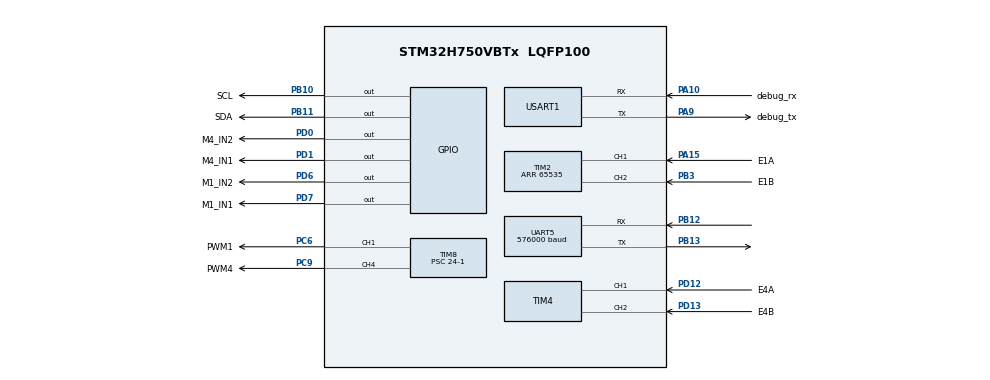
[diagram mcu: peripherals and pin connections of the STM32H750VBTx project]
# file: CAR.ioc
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CORTEX_M7.default_mode_Activation=1
Mcu.Family=STM32H7
Mcu.Name=STM32H750VBTx
Mcu.Package=LQFP100
NVIC.PriorityGroup=NVIC_PRIORITYGROUP_4
NVIC.TIM1_UP_IRQn=true\:15\:0\:false\:false\:true\:false\:true\:true
NVIC.TIM3_IRQn=true\:3\:0\:true\:false\:true\:true\:true\:true
NVIC.TimeBase=TIM1_UP_IRQn
NVIC.TimeBaseIP=TIM1
NVIC.UART5_IRQn=true\:2\:0\:true\:false\:true\:true\:true\:true
PA10.GPIO_Label=debug_rx
PA10.Mode=Asynchronous
PA10.Signal=USART1_RX
PA13\ (JTMS/SWDIO).Signal=DEBUG_JTMS-SWDIO
PA15\ (JTDI).GPIO_Label=E1A
PA15\ (JTDI).Signal=S_TIM2_CH1_ETR
PA9.GPIO_Label=debug_tx
PA9.Mode=Asynchronous
PA9.Signal=USART1_TX
PB10.GPIO_Label=SCL
PB10.GPIO_ModeDefaultOutputPP=GPIO_MODE_OUTPUT_OD
PB10.GPIO_PuPd=GPIO_NOPULL
PB10.GPIO_Speed=GPIO_SPEED_FREQ_HIGH
PB10.PinState=GPIO_PIN_SET
PB10.Signal=GPIO_Output
PB11.GPIO_Label=SDA
PB11.GPIO_ModeDefaultOutputPP=GPIO_MODE_OUTPUT_OD
PB11.GPIO_PuPd=GPIO_NOPULL
PB11.GPIO_Speed=GPIO_SPEED_FREQ_HIGH
PB11.PinState=GPIO_PIN_SET
PB11.Signal=GPIO_Output
PB12.Mode=Asynchronous
PB12.Signal=UART5_RX
PB13.Mode=Asynchronous
PB13.Signal=UART5_TX
PB3\ (JTDO/TRACESWO).GPIO_Label=E1B
PB3\ (JTDO/TRACESWO).Signal=S_TIM2_CH2
PC6.GPIO_Label=PWM1
PC6.Signal=S_TIM8_CH1
PC9.GPIO_Label=PWM4
PC9.Signal=S_TIM8_CH4
PD0.GPIO_Label=M4_IN2
PD0.Signal=GPIO_Output
PD1.GPIO_Label=M4_IN1
PD1.Signal=GPIO_Output
PD12.GPIO_Label=E4A
PD12.Signal=S_TIM4_CH1
PD13.GPIO_Label=E4B
PD13.Signal=S_TIM4_CH2
PD6.GPIO_Label=M1_IN2
PD6.Signal=GPIO_Output
PD7.GPIO_Label=M1_IN1
PD7.Signal=GPIO_Output
PH0-OSC_IN\ (PH0).Mode=HSE-External-Oscillator
PH0-OSC_IN\ (PH0).Signal=RCC_OSC_IN
PH1-OSC_OUT\ (PH1).Mode=HSE-External-Oscillator
PH1-OSC_OUT\ (PH1).Signal=RCC_OSC_OUT
ProjectManager.HeapSize=0x200
ProjectManager.StackSize=0x400
ProjectManager.TargetToolchain=MDK-ARM V5.32
RCC.ADCFreq_Value=24187500
RCC.APB1Freq_Value=120000000
RCC.APB2Freq_Value=120000000
RCC.APB3Freq_Value=120000000
RCC.APB4Freq_Value=120000000
RCC.CortexFreq_Value=480000000
RCC.D1PPRE=RCC_APB3_DIV2
RCC.D2PPRE1=RCC_APB1_DIV2
RCC.D2PPRE2=RCC_APB2_DIV2
RCC.D3PPRE=RCC_APB4_DIV2
RCC.DIVM1=1
RCC.DIVN1=80
RCC.HCLKFreq_Value=240000000
RCC.HPRE=RCC_HCLK_DIV2
RCC.HSE_VALUE=12000000
RCC.PLL2FRACN=0
RCC.PLL3FRACN=0
RCC.PLLFRACN=0
RCC.PLLSourceVirtual=RCC_PLLSOURCE_HSE
RCC.SYSCLKFreq_VALUE=480000000
RCC.SYSCLKSource=RCC_SYSCLKSOURCE_PLLCLK
RCC.USBFreq_Value=480000000
SH.S_TIM2_CH1_ETR.0=TIM2_CH1,Encoder_Interface
SH.S_TIM2_CH2.0=TIM2_CH2,Encoder_Interface
SH.S_TIM4_CH1.0=TIM4_CH1,Encoder_Interface
SH.S_TIM4_CH2.0=TIM4_CH2,Encoder_Interface
SH.S_TIM8_CH1.0=TIM8_CH1,PWM Generation1 CH1
SH.S_TIM8_CH4.0=TIM8_CH4,PWM Generation4 CH4
TIM2.EncoderMode=TIM_ENCODERMODE_TI12
TIM2.IC1Filter=10
TIM2.IC2Filter=10
TIM2.Period=65535
TIM3.Period=20-1
TIM3.Prescaler=24-1
TIM4.EncoderMode=TIM_ENCODERMODE_TI12
TIM4.IC1Filter=10
TIM4.IC2Filter=10
TIM8.Channel-PWM\ Generation1\ CH1=TIM_CHANNEL_1
TIM8.Channel-PWM\ Generation4\ CH4=TIM_CHANNEL_4
TIM8.Period=1000-1
TIM8.Prescaler=24-1
UART5.BaudRate=576000
USART1.VirtualMode-Asynchronous=VM_ASYNC
VP_MEMORYMAP_VS_MEMORYMAP.Mode=CurAppReg
VP_SYS_VS_tim1.Mode=TIM1
VP_TIM3_VS_ClockSourceINT.Mode=Internal
board=custom

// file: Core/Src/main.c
/* USER CODE BEGIN Header */
/**
  ******************************************************************************
  * @file           : main.c
  * @brief          : Main program body
  ******************************************************************************
  * @attention
  *
  * Copyright (c) 2026 STMicroelectronics.
  * All rights reserved.
  *
  * This software is licensed under terms that can be found in the LICENSE file
  * in the root directory of this software component.
  * If no LICENSE file comes with this software, it is provided AS-IS.
  *
  ******************************************************************************
  */
/* USER CODE END Header */
#include "main.h"
#include "memorymap.h"
#include "tim.h"
#include "usart.h"
#include "gpio.h"

/* USER CODE BEGIN Includes */
#include "Car.h"
#include "ros_protocol.h"
/* USER CODE END Includes */

void SystemClock_Config(void);
static void MPU_Config(void);

int main(void)
{

  /* MPU Configuration--------------------------------------------------------*/
  MPU_Config();

  /* MCU Configuration--------------------------------------------------------*/

  /* Reset of all peripherals, Initializes the Flash interface and the Systick. */
  HAL_Init();

  /* Configure the system clock */
  SystemClock_Config();

  /* Initialize all configured peripherals */
  MX_GPIO_Init();
  MX_TIM2_Init();
  MX_TIM4_Init();
  MX_TIM8_Init();
  MX_USART1_UART_Init();
  MX_TIM3_Init();
  MX_UART5_Init();
  /* USER CODE BEGIN 2 */
    HAL_TIM_PWM_Start(&htim8, TIM_CHANNEL_1);
    HAL_TIM_PWM_Start(&htim8, TIM_CHANNEL_4);
    HAL_TIM_Encoder_Start(&htim4, TIM_CHANNEL_ALL);
    HAL_TIM_Encoder_Start(&htim2, TIM_CHANNEL_ALL);
    RosProtocol_Init(&huart5);
  /* USER CODE END 2 */

  /* Infinite loop */
  /* USER CODE BEGIN WHILE */
    Car_Init();
  while (1)
  {

    /* USER CODE END WHILE */

  }
}

void SystemClock_Config(void)
{
  RCC_OscInitTypeDef RCC_OscInitStruct = {0};
  RCC_ClkInitTypeDef RCC_ClkInitStruct = {0};

  /** Supply configuration update enable
  */
  HAL_PWREx_ConfigSupply(PWR_LDO_SUPPLY);

  /** Configure the main internal regulator output voltage
  */
  __HAL_PWR_VOLTAGESCALING_CONFIG(PWR_REGULATOR_VOLTAGE_SCALE0);

  while(!__HAL_PWR_GET_FLAG(PWR_FLAG_VOSRDY)) {}

  /** Initializes the RCC Oscillators according to the specified parameters
  * in the RCC_OscInitTypeDef structure.
  */
  RCC_OscInitStruct.OscillatorType = RCC_OSCILLATORTYPE_HSE;
  RCC_OscInitStruct.HSEState = RCC_HSE_ON;
  RCC_OscInitStruct.PLL.PLLState = RCC_PLL_ON;
  RCC_OscInitStruct.PLL.PLLSource = RCC_PLLSOURCE_HSE;
  RCC_OscInitStruct.PLL.PLLM = 1;
  RCC_OscInitStruct.PLL.PLLN = 80;
  RCC_OscInitStruct.PLL.PLLP = 2;
  RCC_OscInitStruct.PLL.PLLQ = 2;
  RCC_OscInitStruct.PLL.PLLR = 2;
  RCC_OscInitStruct.PLL.PLLRGE = RCC_PLL1VCIRANGE_3;
  RCC_OscInitStruct.PLL.PLLVCOSEL = RCC_PLL1VCOWIDE;
  RCC_OscInitStruct.PLL.PLLFRACN = 0;
  if (HAL_RCC_OscConfig(&RCC_OscInitStruct) != HAL_OK)
  {
    Error_Handler();
  }

  /** Initializes the CPU, AHB and APB buses clocks
  */
  RCC_ClkInitStruct.ClockType = RCC_CLOCKTYPE_HCLK|RCC_CLOCKTYPE_SYSCLK
                              |RCC_CLOCKTYPE_PCLK1|RCC_CLOCKTYPE_PCLK2
                              |RCC_CLOCKTYPE_D3PCLK1|RCC_CLOCKTYPE_D1PCLK1;
  RCC_ClkInitStruct.SYSCLKSource = RCC_SYSCLKSOURCE_PLLCLK;
  RCC_ClkInitStruct.SYSCLKDivider = RCC_SYSCLK_DIV1;
  RCC_ClkInitStruct.AHBCLKDivider = RCC_HCLK_DIV2;
  RCC_ClkInitStruct.APB3CLKDivider = RCC_APB3_DIV2;
  RCC_ClkInitStruct.APB1CLKDivider = RCC_APB1_DIV2;
  RCC_ClkInitStruct.APB2CLKDivider = RCC_APB2_DIV2;
  RCC_ClkInitStruct.APB4CLKDivider = RCC_APB4_DIV2;

  if (HAL_RCC_ClockConfig(&RCC_ClkInitStruct, FLASH_LATENCY_4) != HAL_OK)
  {
    Error_Handler();
  }
}

 /* MPU Configuration */

void MPU_Config(void)
{
  MPU_Region_InitTypeDef MPU_InitStruct = {0};

  /* Disables the MPU */
  HAL_MPU_Disable();

  /** Initializes and configures the Region and the memory to be protected
  */
  MPU_InitStruct.Enable = MPU_REGION_ENABLE;
  MPU_InitStruct.Number = MPU_REGION_NUMBER0;
  MPU_InitStruct.BaseAddress = 0x0;
  MPU_InitStruct.Size = MPU_REGION_SIZE_4GB;
  MPU_InitStruct.SubRegionDisable = 0x87;
  MPU_InitStruct.TypeExtField = MPU_TEX_LEVEL0;
  MPU_InitStruct.AccessPermission = MPU_REGION_NO_ACCESS;
  MPU_InitStruct.DisableExec = MPU_INSTRUCTION_ACCESS_DISABLE;
  MPU_InitStruct.IsShareable = MPU_ACCESS_SHAREABLE;
  MPU_InitStruct.IsCacheable = MPU_ACCESS_NOT_CACHEABLE;
  MPU_InitStruct.IsBufferable = MPU_ACCESS_NOT_BUFFERABLE;

  HAL_MPU_ConfigRegion(&MPU_InitStruct);
  /* Enables the MPU */
  HAL_MPU_Enable(MPU_PRIVILEGED_DEFAULT);

}

//void HAL_TIM_PeriodElapsedCallback(TIM_HandleTypeDef *htim)
//{
//  /* USER CODE BEGIN Callback 0 */

//  /* USER CODE END Callback 0 */
//  if (htim->Instance == TIM1)
//  {
//    HAL_IncTick();
//  }
//  /* USER CODE BEGIN Callback 1 */

//  /* USER CODE END Callback 1 */
//}

void Error_Handler(void)
{
  __disable_irq();
  while (1)
  {
  }
}
